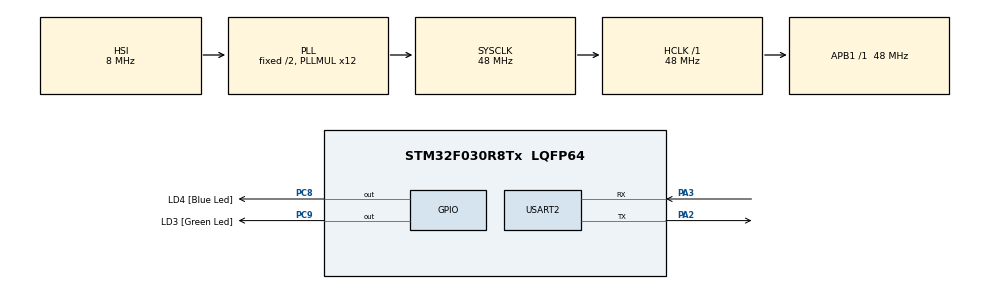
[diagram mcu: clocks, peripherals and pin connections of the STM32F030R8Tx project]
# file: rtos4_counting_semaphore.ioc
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Mcu.Family=STM32F0
FREERTOS.Tasks01=defaultTask,0,128,StartDefaultTask,Default,NULL,Dynamic,NULL,NULL
PC9.GPIO_Label=LD3 [Green Led]
PA14.GPIO_Label=SWCLK
PC8.Signal=GPIO_Output
NVIC.USART2_IRQn=true\:3\:0\:false\:false\:true\:true\:true\:true
RCC.SYSCLKSource=RCC_SYSCLKSOURCE_PLLCLK
ProjectManager.StackSize=0x400
PC8.GPIO_Label=LD4 [Blue Led]
PA3.Mode=Asynchronous
PA13.Signal=SYS_SWDIO
ProjectManager.TargetToolchain=STM32CubeIDE
RCC.HCLKFreq_Value=48000000
RCC.AHBFreq_Value=48000000
board=STM32F0308-DISCO
USART2.VirtualMode-Asynchronous=VM_ASYNC
RCC.PLLMUL=RCC_PLL_MUL12
PA14.Mode=Serial_Wire
VP_SYS_VS_tim1.Mode=TIM1
VP_FREERTOS_VS_CMSIS_V1.Mode=CMSIS_V1
PA13.Mode=Serial_Wire
Mcu.Name=STM32F030R8Tx
PA2.Signal=USART2_TX
PA13.GPIO_Label=SWDIO
RCC.SYSCLKFreq_VALUE=48000000
Mcu.Package=LQFP64
FREERTOS.configUSE_COUNTING_SEMAPHORES=1
NVIC.TimeBase=TIM1_BRK_UP_TRG_COM_IRQn
NVIC.TimeBaseIP=TIM1
PA14.Signal=SYS_SWCLK
ProjectManager.HeapSize=0x200
RCC.APB1TimFreq_Value=48000000
PA2.Mode=Asynchronous
PC9.Signal=GPIO_Output
RCC.APB1Freq_Value=48000000
NVIC.TIM1_BRK_UP_TRG_COM_IRQn=true\:0\:0\:false\:false\:true\:false\:false\:true
PA3.Signal=USART2_RX

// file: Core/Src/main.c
/* USER CODE BEGIN Header */
/**
  ******************************************************************************
  * @file           : main.c
  * @brief          : Main program body
  ******************************************************************************
  * @attention
  *
  * <h2><center>&copy; Copyright (c) 2021 STMicroelectronics.
  * All rights reserved.</center></h2>
  *
  * This software component is licensed by ST under BSD 3-Clause license,
  * the "License"; You may not use this file except in compliance with the
  * License. You may obtain a copy of the License at:
  *                        opensource.org/licenses/BSD-3-Clause
  *
  ******************************************************************************
  */
/* USER CODE END Header */
#include "main.h"
//#include "cmsis_os.h"
#include "FreeRTOS.h"
#include "task.h"
#include "timers.h"
#include "queue.h"
#include "semphr.h"
#include "event_groups.h"
#include "string.h"
#include "stdlib.h"

UART_HandleTypeDef huart2;

void SystemClock_Config(void);
static void MX_GPIO_Init(void);
static void MX_USART2_UART_Init(void);

// create task defines
TaskHandle_t HPThandler;
void HPT_TASK (void *pvParameters);

TaskHandle_t MPThandler;
void MPT_TASK (void *pvParameters);

TaskHandle_t LPThandler;
void LPT_TASK (void *pvParameters);

TaskHandle_t VLPThandler;
void VLPT_TASK (void *pvParameters);

// semaphore related
SemaphoreHandle_t CountingSem;

// resource related
int resource[3] = {111,222,333};
int indx = 0;

// uart related
uint8_t rx_data = 0;
/* USER CODE BEGIN 0 */
void print(char *msg)
{
	HAL_UART_Transmit(&huart2, (uint8_t *)msg, strlen(msg), 100);
}
/* USER CODE END 0 */

int main(void)
{

  /* MCU Configuration--------------------------------------------------------*/

  /* Reset of all peripherals, Initializes the Flash interface and the Systick. */
  HAL_Init();

  /* Configure the system clock */
  SystemClock_Config();

  /* Initialize all configured peripherals */
  MX_GPIO_Init();
  MX_USART2_UART_Init();
  CountingSem = xSemaphoreCreateCounting(3,0);
  if (CountingSem == NULL) HAL_UART_Transmit(&huart2, (uint8_t *) "Unable to Create Semaphore\n\n", 28, 100);
  else HAL_UART_Transmit(&huart2, (uint8_t *) "Counting Semaphore created successfully\n\n", 41, 1000);
  /* add mutexes, ... */
  /* USER CODE END RTOS_MUTEX */
  // create TASKS

  xTaskCreate(HPT_TASK, "HPT", 128, NULL, 3, &HPThandler);
  xTaskCreate(MPT_TASK, "MPT", 128, NULL, 2, &MPThandler);
  xTaskCreate(LPT_TASK, "LPT", 128, NULL, 1, &LPThandler);
  xTaskCreate(VLPT_TASK, "VLPT", 128, NULL, 0, &VLPThandler);

  vTaskStartScheduler();

  /* Create the thread(s) */
  /* definition and creation of defaultTask */

  /* Start scheduler */

  /* We should never get here as control is now taken by the scheduler */
  /* Infinite loop */
  while (1)
  {

  }
}

void SystemClock_Config(void)
{
  RCC_OscInitTypeDef RCC_OscInitStruct = {0};
  RCC_ClkInitTypeDef RCC_ClkInitStruct = {0};

  /** Initializes the RCC Oscillators according to the specified parameters
  * in the RCC_OscInitTypeDef structure.
  */
  RCC_OscInitStruct.OscillatorType = RCC_OSCILLATORTYPE_HSI;
  RCC_OscInitStruct.HSIState = RCC_HSI_ON;
  RCC_OscInitStruct.HSICalibrationValue = RCC_HSICALIBRATION_DEFAULT;
  RCC_OscInitStruct.PLL.PLLState = RCC_PLL_ON;
  RCC_OscInitStruct.PLL.PLLSource = RCC_PLLSOURCE_HSI;
  RCC_OscInitStruct.PLL.PLLMUL = RCC_PLL_MUL12;
  RCC_OscInitStruct.PLL.PREDIV = RCC_PREDIV_DIV1;
  if (HAL_RCC_OscConfig(&RCC_OscInitStruct) != HAL_OK)
  {
    Error_Handler();
  }
  /** Initializes the CPU, AHB and APB buses clocks
  */
  RCC_ClkInitStruct.ClockType = RCC_CLOCKTYPE_HCLK|RCC_CLOCKTYPE_SYSCLK
                              |RCC_CLOCKTYPE_PCLK1;
  RCC_ClkInitStruct.SYSCLKSource = RCC_SYSCLKSOURCE_PLLCLK;
  RCC_ClkInitStruct.AHBCLKDivider = RCC_SYSCLK_DIV1;
  RCC_ClkInitStruct.APB1CLKDivider = RCC_HCLK_DIV1;

  if (HAL_RCC_ClockConfig(&RCC_ClkInitStruct, FLASH_LATENCY_1) != HAL_OK)
  {
    Error_Handler();
  }
}

static void MX_USART2_UART_Init(void)
{

  huart2.Instance = USART2;
  huart2.Init.BaudRate = 38400;
  huart2.Init.WordLength = UART_WORDLENGTH_8B;
  huart2.Init.StopBits = UART_STOPBITS_1;
  huart2.Init.Parity = UART_PARITY_NONE;
  huart2.Init.Mode = UART_MODE_TX_RX;
  huart2.Init.HwFlowCtl = UART_HWCONTROL_NONE;
  huart2.Init.OverSampling = UART_OVERSAMPLING_16;
  huart2.Init.OneBitSampling = UART_ONE_BIT_SAMPLE_DISABLE;
  huart2.AdvancedInit.AdvFeatureInit = UART_ADVFEATURE_NO_INIT;
  if (HAL_UART_Init(&huart2) != HAL_OK)
  {
    Error_Handler();
  }

}

static void MX_GPIO_Init(void)
{
  GPIO_InitTypeDef GPIO_InitStruct = {0};

  /* GPIO Ports Clock Enable */
  __HAL_RCC_GPIOA_CLK_ENABLE();
  __HAL_RCC_GPIOC_CLK_ENABLE();

  /*Configure GPIO pin Output Level */
  HAL_GPIO_WritePin(GPIOC, LD4_Pin|LD3_Pin, GPIO_PIN_RESET);

  /*Configure GPIO pins : LD4_Pin LD3_Pin */
  GPIO_InitStruct.Pin = LD4_Pin|LD3_Pin;
  GPIO_InitStruct.Mode = GPIO_MODE_OUTPUT_PP;
  GPIO_InitStruct.Pull = GPIO_NOPULL;
  GPIO_InitStruct.Speed = GPIO_SPEED_FREQ_LOW;
  HAL_GPIO_Init(GPIOC, &GPIO_InitStruct);

}

void HPT_TASK (void *pvParameters)
{
	char sresource[3];
	int semcount = 0;
	char ssemcount[2];

	// Give 3 semaphores at the beginning..
	xSemaphoreGive(CountingSem);
	xSemaphoreGive(CountingSem);
	xSemaphoreGive(CountingSem);

	while (1)
	{
		char str[150];
		strcpy(str, "Entered HPT Task\n About to ACQUIRE the Semaphore\n ");
		semcount = uxSemaphoreGetCount(CountingSem);
		itoa (semcount, ssemcount, 10);
		strcat (str, "Tokens available are: ");
		strcat (str, ssemcount);
		strcat (str, "\n\n");
		HAL_UART_Transmit(&huart2, (uint8_t *)str, strlen (str), HAL_MAX_DELAY);

		xSemaphoreTake(CountingSem, portMAX_DELAY);

		itoa (resource[indx], sresource, 10);
		strcpy (str, "Leaving HPT Task\n Data ACCESSED is:: ");
		strcat (str, sresource);
		strcat (str, "\n Not releasing the Semaphore\n\n\n");
		HAL_UART_Transmit(&huart2, (uint8_t *)str, strlen (str), HAL_MAX_DELAY);

		indx++;
		if (indx>2) indx=0;

		vTaskDelay(3000);
//		vTaskDelete(NULL);
	}
}

void MPT_TASK (void *pvParameters)
{
	char sresource[3];
	int semcount = 0;
	char ssemcount[2];

	// Give 3 semaphores at the beginning..
	//xSemaphoreGive(CountingSem);
	//xSemaphoreGive(CountingSem);
	//xSemaphoreGive(CountingSem);

	while (1)
	{
		char str[150];
		strcpy(str, "Entered MPT Task\n About to ACQUIRE the Semaphore\n ");
		semcount = uxSemaphoreGetCount(CountingSem);
		itoa (semcount, ssemcount, 10);
		strcat (str, "Tokens available are: ");
		strcat (str, ssemcount);
		strcat (str, "\n\n");
		HAL_UART_Transmit(&huart2, (uint8_t *)str, strlen (str), HAL_MAX_DELAY);

		xSemaphoreTake(CountingSem, portMAX_DELAY);

		itoa (resource[indx], sresource, 10);
		strcpy (str, "Leaving MPT Task\n Data ACCESSED is:: ");
		strcat (str, sresource);
		strcat (str, "\n Not releasing the Semaphore\n\n\n");
		HAL_UART_Transmit(&huart2, (uint8_t *)str, strlen (str), HAL_MAX_DELAY);

		indx++;
		if (indx>2) indx=0;

		vTaskDelay(3000);
//		vTaskDelete(NULL);
	}
}

void LPT_TASK (void *pvParameters)
{
	char sresource[3];
	int semcount = 0;
	char ssemcount[2];

	// Give 3 semaphores at the beginning..
	//xSemaphoreGive(CountingSem);
	//xSemaphoreGive(CountingSem);
	//xSemaphoreGive(CountingSem);

	while (1)
	{
		char str[150];
		strcpy(str, "Entered LPT Task\n About to ACQUIRE the Semaphore\n ");
		semcount = uxSemaphoreGetCount(CountingSem);
		itoa (semcount, ssemcount, 10);
		strcat (str, "Tokens available are: ");
		strcat (str, ssemcount);
		strcat (str, "\n\n");
		HAL_UART_Transmit(&huart2, (uint8_t *)str, strlen (str), HAL_MAX_DELAY);

		xSemaphoreTake(CountingSem, portMAX_DELAY);

		itoa (resource[indx], sresource, 10);
		strcpy (str, "Leaving LPT Task\n Data ACCESSED is:: ");
		strcat (str, sresource);
		strcat (str, "\n Not releasing the Semaphore\n\n\n");
		HAL_UART_Transmit(&huart2, (uint8_t *)str, strlen (str), HAL_MAX_DELAY);

		indx++;
		if (indx>2) indx=0;

		vTaskDelay(3000);
//		vTaskDelete(NULL);
	}
}

void VLPT_TASK (void *pvParameters)
{
	char sresource[3];
	int semcount = 0;
	char ssemcount[2];

	// Give 3 semaphores at the beginning..
	//xSemaphoreGive(CountingSem);
	//xSemaphoreGive(CountingSem);
	//xSemaphoreGive(CountingSem);

	while (1)
	{
		char str[150];
		strcpy(str, "Entered VLHPT Task\n About to ACQUIRE the Semaphore\n ");
		semcount = uxSemaphoreGetCount(CountingSem);
		itoa (semcount, ssemcount, 10);
		strcat (str, "Tokens available are: ");
		strcat (str, ssemcount);
		strcat (str, "\n\n");
		HAL_UART_Transmit(&huart2, (uint8_t *)str, strlen (str), HAL_MAX_DELAY);

		xSemaphoreTake(CountingSem, portMAX_DELAY);

		itoa (resource[indx], sresource, 10);
		strcpy (str, "Leaving VLPT Task\n Data ACCESSED is:: ");
		strcat (str, sresource);
		strcat (str, "\n Not releasing the Semaphore\n\n\n");
		HAL_UART_Transmit(&huart2, (uint8_t *)str, strlen (str), HAL_MAX_DELAY);

		indx++;
		if (indx>2) indx=0;

		vTaskDelay(3000);
//		vTaskDelete(NULL);
	}
}

void HAL_UART_RxCpltCallback(UART_HandleTypeDef *huart)
{
	HAL_UART_Receive_IT(huart, &rx_data, 1);
	if (rx_data == 'r')
	{
		// release the semaphore here
		 /* The xHigherPriorityTaskWoken parameter must be initialized to pdFALSE as
		 it will get set to pdTRUE inside the interrupt safe API function if a
		 context switch is required. */
		BaseType_t xHigherPriorityTaskWoken = pdFALSE;

		xSemaphoreGiveFromISR(CountingSem, &xHigherPriorityTaskWoken);  // ISR SAFE VERSION
		xSemaphoreGiveFromISR(CountingSem, &xHigherPriorityTaskWoken);  // ISR SAFE VERSION
		xSemaphoreGiveFromISR(CountingSem, &xHigherPriorityTaskWoken);  // ISR SAFE VERSION

		/* Pass the xHigherPriorityTaskWoken value into portEND_SWITCHING_ISR(). If
		 xHigherPriorityTaskWoken was set to pdTRUE inside xSemaphoreGiveFromISR()
		 then calling portEND_SWITCHING_ISR() will request a context switch. If
		 xHigherPriorityTaskWoken is still pdFALSE then calling
		 portEND_SWITCHING_ISR() will have no effect */

		portEND_SWITCHING_ISR( xHigherPriorityTaskWoken );
	}
}
/* USER CODE END 4 */

 /**
  * @brief  Period elapsed callback in non blocking mode
  * @note   This function is called  when TIM1 interrupt took place, inside
  * HAL_TIM_IRQHandler(). It makes a direct call to HAL_IncTick() to increment
  * a global variable "uwTick" used as application time base.
  * @param  htim : TIM handle
  * @retval None
  */
void HAL_TIM_PeriodElapsedCallback(TIM_HandleTypeDef *htim)
{
  if (htim->Instance == TIM1) {
    HAL_IncTick();
  }
}

void Error_Handler(void)
{
  __disable_irq();
  while (1)
  {
  }
}

/************************ (C) COPYRIGHT STMicroelectronics *****END OF FILE****/
